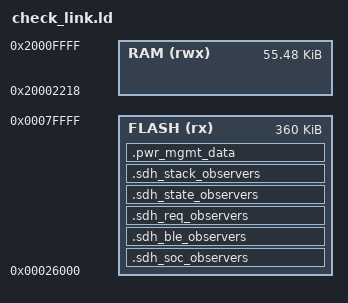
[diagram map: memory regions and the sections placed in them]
/* GNU regression link only. Keep the existing Keil project as the production build. */
MEMORY
{
  FLASH (rx) : ORIGIN = 0x26000, LENGTH = 0x5A000
  RAM (rwx)  : ORIGIN = 0x20002218, LENGTH = 0xDDE8
}

SECTIONS
{
  .sdh_soc_observers : {
    PROVIDE(__start_sdh_soc_observers = .);
    KEEP(*(SORT(.sdh_soc_observers*)))
    PROVIDE(__stop_sdh_soc_observers = .);
  } > FLASH
  .sdh_ble_observers : {
    PROVIDE(__start_sdh_ble_observers = .);
    KEEP(*(SORT(.sdh_ble_observers*)))
    PROVIDE(__stop_sdh_ble_observers = .);
  } > FLASH
  .sdh_req_observers : {
    PROVIDE(__start_sdh_req_observers = .);
    KEEP(*(SORT(.sdh_req_observers*)))
    PROVIDE(__stop_sdh_req_observers = .);
  } > FLASH
  .sdh_state_observers : {
    PROVIDE(__start_sdh_state_observers = .);
    KEEP(*(SORT(.sdh_state_observers*)))
    PROVIDE(__stop_sdh_state_observers = .);
  } > FLASH
  .sdh_stack_observers : {
    PROVIDE(__start_sdh_stack_observers = .);
    KEEP(*(SORT(.sdh_stack_observers*)))
    PROVIDE(__stop_sdh_stack_observers = .);
  } > FLASH
  .pwr_mgmt_data : {
    PROVIDE(__start_pwr_mgmt_data = .);
    KEEP(*(SORT(.pwr_mgmt_data*)))
    PROVIDE(__stop_pwr_mgmt_data = .);
  } > FLASH
}
INSERT AFTER .text;

SECTIONS
{
  .fs_data : {
    PROVIDE(__start_fs_data = .);
    KEEP(*(.fs_data))
    PROVIDE(__stop_fs_data = .);
  } > RAM
}
INSERT AFTER .data;

INCLUDE "nrf_common.ld"
